# CORTEXM register map
File version: 1.0
Registers are 32-bit, read-write, reset 0x0 unless marked. A register's access mark holds for its fields unless they carry their own. Offsets are from the block's base; lines under a group give offsets from that group; [hi:lo] are bit positions; {n}, {i} and the like mark numbered series; 'fields as' and 'values as' point back to an identical list; <NAME> marks a mode.

## Memory map
0xE000ED00 CM_SCB size 0x90 — System Control Block
0xE000EDF0 CM_DCB size 0x10 — Debug Control Block

## CM_SCB — System Control Block
Base 0xE000ED00
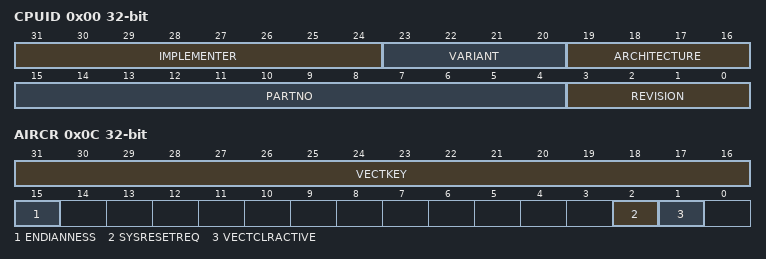
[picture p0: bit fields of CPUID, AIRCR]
0x00 CPUID ro — Provides identification information for the processor
  [31:24] IMPLEMENTER — Implementer code assigned by ARM
    65=ARM
  [23:20] VARIANT — IMPLEMENTATION DEFINED variant number
  [19:16] ARCHITECTURE — Reads as 0xF
  [15:4] PARTNO — IMPLEMENTATION DEFINED part number
    0xC20=CORTEXM0; 0xC23=CORTEXM3; 0xC24=CORTEXM4; 0xC27=CORTEXM7; 0xC60=CORTEXM0P; 0xD20=CORTEXM23; 0xD21=CORTEXM33
  [3:0] REVISION — IMPLEMENTATION DEFINED revision number
0x0C AIRCR — Sets or returns interrupt control data
  [31:16] VECTKEY — Vector Key. The value 0x05FA must be written to this register.
    0x5FA=KEY (Vector Key)
  [15] ENDIANNESS — Indicates the memory system endianness
    0=Little endian; 1=Big endian
  [2] SYSRESETREQ — System Reset Request
    0=Do not request a reset; 1=Request reset
  [1] VECTCLRACTIVE — Writing 1 to this bit clears all active state information for fixed and configurable exceptions

## CM_DCB — Debug Control Block
Base 0xE000EDF0
0x00 DHCSR — Controls halting debug
  [25] S_RESET_ST — Indicates whether the processor has been reset since the last read of DHCSR
    0=No reset since last DHCSR read; 1=At least one reset since last DHCSR read
  [24] S_RETIRE_ST — Set to 1 every time the processor retires one or more instructions
    0=No instruction retired since last DHCSR read; 1=At least one instruction retired since last DHCSR read
  [19] S_LOCKUP — Indicates whether the processor is locked up because of an unrecoverable exception
    0=Not locked up; 1=Locked up
  [18] S_SLEEP — Indicates whether the processor is sleeping
    0=Not sleeping; 1=Sleeping
  [17] S_HALT — Indicates whether the processor is in Debug state
    0=In Non-debug state; 1=In Debug state
  [31:16] DBGKEY — Debug key
    0xA05F=KEY (Vector Key)
  [16] S_REGRDY — A handshake flag for transfers through the DCRDR
    0=There has been a write to the DCRDR, but the transfer is not complete; 1=The transfer to or from the DCRDR is complete
  [5] C_SNAPSTALL — Allow imprecise entry to Debug state
    0=No action; 1=Allow imprecise entry to Debug state, for example by forcing any stalled load or store instruction to complete
  [3] C_MASKINTS — When debug is enabled, the debugger can write to this bit to mask PendSV, SysTick and external configurable interrupts
    0=Do not mask; 1=Mask PendSV, SysTick and external configurable interrupts
  [2] C_STEP — Processor step bit
    0=No effect; 1=Single step enabled
  [1] C_HALT — Processor halt bit
    0=Causes the processor to leave Debug state, if in Debug state; 1=Halt the processor
  [0] C_DEBUGEN — Halting debug enable bit
    0=Disabled; 1=Enabled
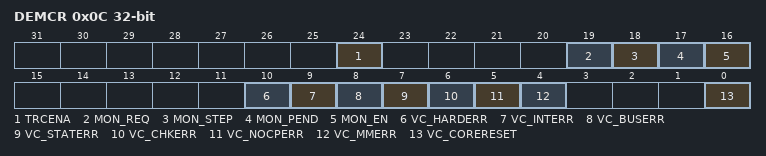
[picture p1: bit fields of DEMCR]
0x0C DEMCR — Manages vector catch behavior and DebugMonitor handling when debugging
  [24] TRCENA — Global enable for all DWT and ITM features
    0=DWT and ITM units disabled; 1=DWT and ITM units enabled
  [19] MON_REQ — DebugMonitor semaphore bit
  [18] MON_STEP — When MON_EN is set to 0, this feature is disabled and the processor ignores MON_STEP
    0=Do not step the processor; 1=Step the processor
  [17] MON_PEND — Sets or clears the pending state of the DebugMonitor exception
    0=Clear the status of the DebugMonitor exception to not pending; 1=Set the status of the DebugMonitor exception to pending
  [16] MON_EN — Enable the DebugMonitor exception
    0=DebugMonitor exception disabled; 1=DebugMonitor exception enabled
  [10] VC_HARDERR — Enable halting debug trap on a HardFault exception
    0=Halting debug trap disabled; 1=Halting debug trap enabled
  [9] VC_INTERR — Enable halting debug trap on a fault occurring during exception entry or exception return
    0=Halting debug trap disabled; 1=Halting debug trap enabled
  [8] VC_BUSERR — Enable halting debug trap on a BusFault exception
    0=Halting debug trap disabled; 1=Halting debug trap enabled
  [7] VC_STATERR — Enable halting debug trap on a UsageFault exception caused by a state information error, for example an Undefined Instruction exception
    0=Halting debug trap disabled; 1=Halting debug trap enabled
  [6] VC_CHKERR — Enable halting debug trap on a UsageFault exception caused by a checking error, for example an alignment check error
    0=Halting debug trap disabled; 1=Halting debug trap enabled
  [5] VC_NOCPERR — Enable halting debug trap on a UsageFault caused by an access to a Coprocessor
    0=Halting debug trap disabled; 1=Halting debug trap enabled
  [4] VC_MMERR — Enable halting debug trap on a MemManage exception
    0=Halting debug trap disabled; 1=Halting debug trap enabled
  [0] VC_CORERESET — Enable Reset Vector Catch
    0=Reset Vector Catch disabled; 1=Reset Vector Catch enabled
